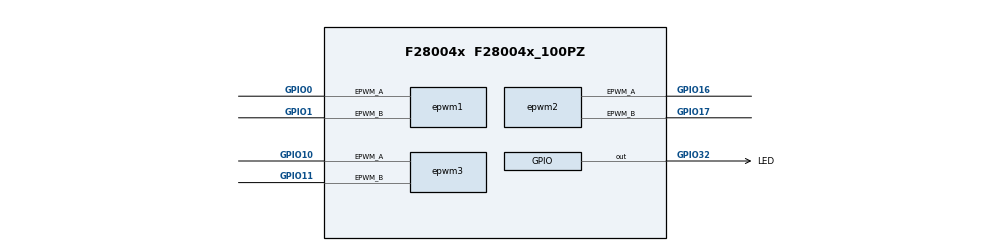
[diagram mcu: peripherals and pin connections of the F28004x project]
/**
 * @cliArgs --device "F28004x" --package "F28004x_100PZ" --part "F28004x_100PZ" --context "system" --product "C2000WARE@5.02.00.00"
 * @versions {"tool":"1.20.0+3587"}
 */

/**
 * Import the modules used in this configuration.
 */
const adc       = scripting.addModule("/driverlib/adc.js", {}, false);
const adc1      = adc.addInstance();
const asysctl   = scripting.addModule("/driverlib/asysctl.js");
const cputimer  = scripting.addModule("/driverlib/cputimer.js", {}, false);
const cputimer1 = cputimer.addInstance();
const epwm      = scripting.addModule("/driverlib/epwm.js", {}, false);
const epwm1     = epwm.addInstance();
const epwm2     = epwm.addInstance();
const epwm3     = epwm.addInstance();
const gpio      = scripting.addModule("/driverlib/gpio.js", {}, false);
const gpio1     = gpio.addInstance();

/**
 * Write custom configuration values to the imported modules.
 */
adc1.$name                   = "myADCA";
adc1.adcClockPrescaler       = "ADC_CLK_DIV_4_0";
adc1.enabledSOCs             = ["ADC_SOC_NUMBER0"];
adc1.soc0SampleWindow        = 10;
adc1.soc0Trigger             = "ADC_TRIGGER_EPWM1_SOCA";
adc1.enabledInts             = ["ADC_INT_NUMBER1"];
adc1.interruptPulseMode      = "ADC_PULSE_END_OF_CONV";
adc1.enableInterrupt1        = true;
adc1.registerInterrupts      = ["1"];
adc1.adcInt1.enableInterrupt = true;

asysctl.analogReference        = "INTERNAL";
asysctl.analogReferenceVoltage = "1P65";

cputimer1.$name                    = "myCPUTIMER0";
cputimer1.timerPeriod              = 10000;
cputimer1.enableInterrupt          = true;
cputimer1.registerInterrupts       = true;
cputimer1.startTimer               = true;
cputimer1.timerInt.enableInterrupt = true;

epwm1.$name                                                      = "myEPWM1";
epwm1.epwmTimebase_period                                        = 5000;
epwm1.epwmTimebase_hsClockDiv                                    = "EPWM_HSCLOCK_DIVIDER_1";
epwm1.epwmTimebase_counterMode                                   = "EPWM_COUNTER_MODE_UP_DOWN";
epwm1.epwmTimebase_forceSyncPulse                                = true;
epwm1.epwmTimebase_syncOutPulseMode                              = "EPWM_SYNC_OUT_PULSE_ON_COUNTER_ZERO";
epwm1.hrpwm_syncSource                                           = "HRPWM_PWMSYNC_SOURCE_ZERO";
epwm1.epwmEventTrigger_enableInterrupt                           = true;
epwm1.epwmEventTrigger_EPWM_SOC_A_triggerEnable                  = true;
epwm1.epwmEventTrigger_EPWM_SOC_A_triggerSource                  = "EPWM_SOC_TBCTR_ZERO_OR_PERIOD";
epwm1.epwmEventTrigger_EPWM_SOC_A_triggerEventPrescalar          = "1";
epwm1.epwmActionQualifier_EPWM_AQ_OUTPUT_A_ON_TIMEBASE_UP_CMPA   = "EPWM_AQ_OUTPUT_LOW";
epwm1.epwmActionQualifier_EPWM_AQ_OUTPUT_A_ON_TIMEBASE_DOWN_CMPA = "EPWM_AQ_OUTPUT_HIGH";
epwm1.epwmCounterCompare_cmpA                                    = 2500;
epwm1.epwm.$assign                                               = "EPWM1";
epwm1.epwm.epwm_aPin.$assign                                     = "GPIO0";
epwm1.epwm.epwm_bPin.$assign                                     = "GPIO1";

epwm2.$name                                                      = "myEPWM5";
epwm2.epwmTimebase_hsClockDiv                                    = "EPWM_HSCLOCK_DIVIDER_1";
epwm2.epwmTimebase_period                                        = 5000;
epwm2.epwmTimebase_counterMode                                   = "EPWM_COUNTER_MODE_UP_DOWN";
epwm2.epwmTimebase_counterModeAfterSync                          = "EPWM_COUNT_MODE_UP_AFTER_SYNC";
epwm2.epwmCounterCompare_cmpA                                    = 2500;
epwm2.epwmActionQualifier_EPWM_AQ_OUTPUT_A_ON_TIMEBASE_UP_CMPA   = "EPWM_AQ_OUTPUT_LOW";
epwm2.epwmActionQualifier_EPWM_AQ_OUTPUT_A_ON_TIMEBASE_DOWN_CMPA = "EPWM_AQ_OUTPUT_HIGH";
epwm2.epwmTimebase_syncOutPulseMode                              = "EPWM_SYNC_OUT_PULSE_ON_EPWMxSYNCIN";
epwm2.epwmTimebase_phaseEnable                                   = true;
epwm2.epwmDeadband_polarityFED                                   = "EPWM_DB_POLARITY_ACTIVE_LOW";
epwm2.epwmDeadband_enableRED                                     = true;
epwm2.epwmDeadband_enableFED                                     = true;
epwm2.epwmDeadband_delayRED                                      = 10;
epwm2.epwmDeadband_delayFED                                      = 10;
epwm2.epwm.$assign                                               = "EPWM5";
epwm2.epwm.epwm_aPin.$assign                                     = "GPIO16";
epwm2.epwm.epwm_bPin.$assign                                     = "GPIO17";

epwm3.epwmTimebase_hsClockDiv                                    = "EPWM_HSCLOCK_DIVIDER_1";
epwm3.epwmTimebase_period                                        = 5000;
epwm3.epwmTimebase_counterMode                                   = "EPWM_COUNTER_MODE_UP_DOWN";
epwm3.epwmTimebase_counterModeAfterSync                          = "EPWM_COUNT_MODE_UP_AFTER_SYNC";
epwm3.epwmCounterCompare_cmpA                                    = 2500;
epwm3.epwmActionQualifier_EPWM_AQ_OUTPUT_A_ON_TIMEBASE_UP_CMPA   = "EPWM_AQ_OUTPUT_LOW";
epwm3.epwmActionQualifier_EPWM_AQ_OUTPUT_A_ON_TIMEBASE_DOWN_CMPA = "EPWM_AQ_OUTPUT_HIGH";
epwm3.epwmTimebase_syncOutPulseMode                              = "EPWM_SYNC_OUT_PULSE_ON_EPWMxSYNCIN";
epwm3.epwmTimebase_phaseEnable                                   = true;
epwm3.epwmDeadband_polarityFED                                   = "EPWM_DB_POLARITY_ACTIVE_LOW";
epwm3.epwmDeadband_enableRED                                     = true;
epwm3.epwmDeadband_enableFED                                     = true;
epwm3.epwmDeadband_delayRED                                      = 10;
epwm3.epwmDeadband_delayFED                                      = 10;
epwm3.$name                                                      = "myEPWM6";
epwm3.epwm.$assign                                               = "EPWM6";
epwm3.epwm.epwm_aPin.$assign                                     = "GPIO10";
epwm3.epwm.epwm_bPin.$assign                                     = "GPIO11";

gpio1.$name           = "LED";
gpio1.direction       = "GPIO_DIR_MODE_OUT";
gpio1.gpioPin.$assign = "GPIO32";
